# DDR32SS0_CTLPHY_WRAP_CTL_CFG_CTLCFG register map
Vendor: Texas Instruments
Registers are 32-bit, read-write, reset 0x0 unless marked. A register's access mark holds for its fields unless they carry their own. Offsets are as the file gives them; [hi:lo] are bit positions; {n}, {i} and the like mark numbered series.

## DDR32SS0_CTLPHY_WRAP_CTL_CFG_CTLCFG (part 6 of 11)
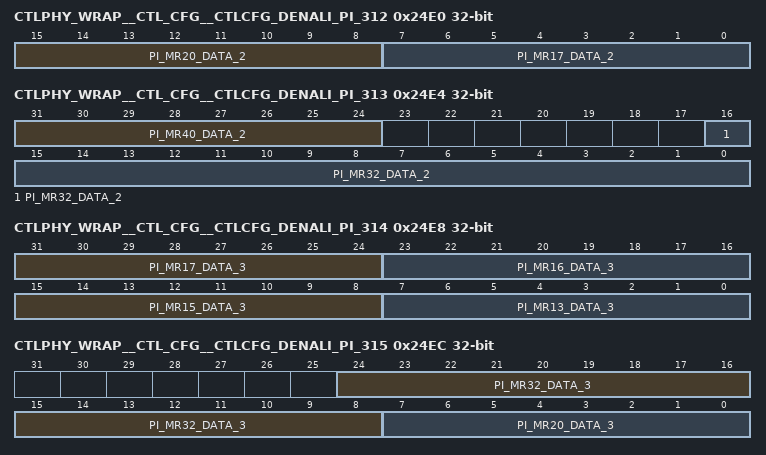
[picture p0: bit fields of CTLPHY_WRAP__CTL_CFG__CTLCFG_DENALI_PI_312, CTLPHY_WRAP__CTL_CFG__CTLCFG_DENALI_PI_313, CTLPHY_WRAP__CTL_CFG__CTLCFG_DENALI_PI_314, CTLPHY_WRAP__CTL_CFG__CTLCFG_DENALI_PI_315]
0x24E0 CTLPHY_WRAP__CTL_CFG__CTLCFG_DENALI_PI_312
  [15:8] PI_MR20_DATA_2 — Data to program into memory mode register 20 for chip select 2.
  [7:0] PI_MR17_DATA_2 — Data to program into memory mode register 17 for chip select 2.
0x24E4 CTLPHY_WRAP__CTL_CFG__CTLCFG_DENALI_PI_313
  [31:24] PI_MR40_DATA_2 — Data to program into memory mode register 40 for chip select 2.
  [16:0] PI_MR32_DATA_2 — Data to program into memory mode register 32 for chip select 2.
0x24E8 CTLPHY_WRAP__CTL_CFG__CTLCFG_DENALI_PI_314
  [31:24] PI_MR17_DATA_3 — Data to program into memory mode register 17 for chip select 3.
  [23:16] PI_MR16_DATA_3 — Data to program into memory mode register 16 for chip select 3.
  [15:8] PI_MR15_DATA_3 — Data to program into memory mode register 15 for chip select 3.
  [7:0] PI_MR13_DATA_3 — Data to program into memory mode register 13 for chip select 3.
0x24EC CTLPHY_WRAP__CTL_CFG__CTLCFG_DENALI_PI_315
  [24:8] PI_MR32_DATA_3 — Data to program into memory mode register 32 for chip select 3.
  [7:0] PI_MR20_DATA_3 — Data to program into memory mode register 20 for chip select 3.
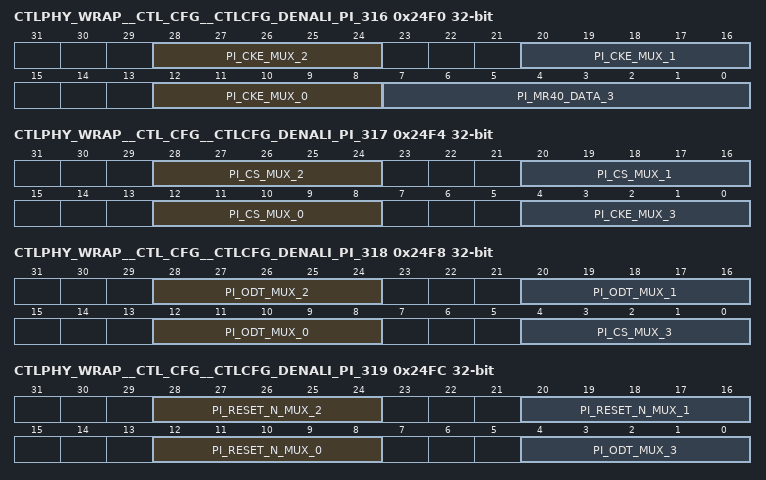
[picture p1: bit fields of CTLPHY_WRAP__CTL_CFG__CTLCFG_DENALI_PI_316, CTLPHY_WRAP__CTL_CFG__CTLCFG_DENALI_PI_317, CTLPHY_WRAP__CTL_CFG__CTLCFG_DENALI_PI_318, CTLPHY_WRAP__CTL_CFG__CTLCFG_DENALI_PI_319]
0x24F0 CTLPHY_WRAP__CTL_CFG__CTLCFG_DENALI_PI_316
  [28:24] PI_CKE_MUX_2 — Command pin CKE_2 mux selector
  [20:16] PI_CKE_MUX_1 — Command pin CKE_1 mux selector
  [12:8] PI_CKE_MUX_0 — Command pin CKE_0 mux selector
  [7:0] PI_MR40_DATA_3 — Data to program into memory mode register 40 for chip select 3.
0x24F4 CTLPHY_WRAP__CTL_CFG__CTLCFG_DENALI_PI_317
  [28:24] PI_CS_MUX_2 — Command pin CS_2 mux selector
  [20:16] PI_CS_MUX_1 — Command pin CS_1 mux selector
  [12:8] PI_CS_MUX_0 — Command pin CS_0 mux selector
  [4:0] PI_CKE_MUX_3 — Command pin CKE_3 mux selector
0x24F8 CTLPHY_WRAP__CTL_CFG__CTLCFG_DENALI_PI_318
  [28:24] PI_ODT_MUX_2 — Command pin ODT_2 mux selector
  [20:16] PI_ODT_MUX_1 — Command pin ODT_1 mux selector
  [12:8] PI_ODT_MUX_0 — Command pin ODT_0 mux selector
  [4:0] PI_CS_MUX_3 — Command pin CS_3 mux selector
0x24FC CTLPHY_WRAP__CTL_CFG__CTLCFG_DENALI_PI_319
  [28:24] PI_RESET_N_MUX_2 — Command pin RESET_N_2 mux selector
  [20:16] PI_RESET_N_MUX_1 — Command pin RESET_N_1 mux selector
  [12:8] PI_RESET_N_MUX_0 — Command pin RESET_N_0 mux selector
  [4:0] PI_ODT_MUX_3 — Command pin ODT_3 mux selector
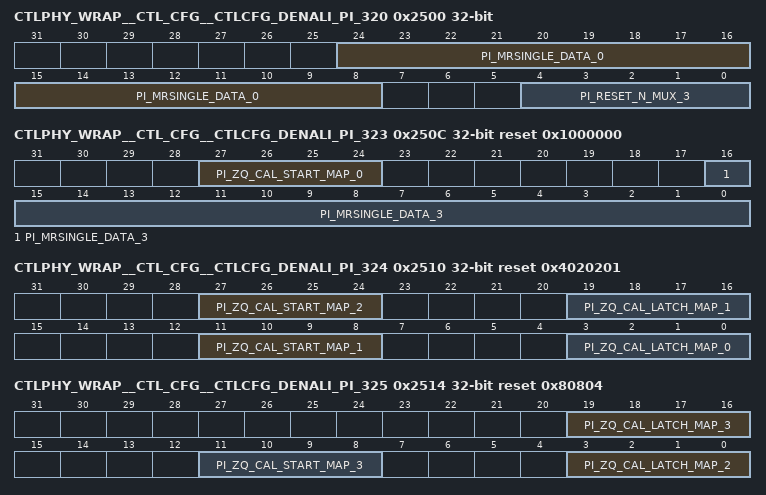
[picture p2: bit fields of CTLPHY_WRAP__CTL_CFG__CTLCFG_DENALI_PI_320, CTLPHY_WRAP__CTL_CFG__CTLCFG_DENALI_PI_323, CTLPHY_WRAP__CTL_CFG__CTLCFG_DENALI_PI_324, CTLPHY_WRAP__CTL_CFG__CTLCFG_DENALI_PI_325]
0x2500 CTLPHY_WRAP__CTL_CFG__CTLCFG_DENALI_PI_320
  [24:8] PI_MRSINGLE_DATA_0 — Data to program into memory mode register single write to chip select 0.
  [4:0] PI_RESET_N_MUX_3 — Command pin RESET_N_3 mux selector
0x2504 CTLPHY_WRAP__CTL_CFG__CTLCFG_DENALI_PI_321
  [16:0] PI_MRSINGLE_DATA_1 — Data to program into memory mode register single write to chip select 1.
0x2508 CTLPHY_WRAP__CTL_CFG__CTLCFG_DENALI_PI_322
  [16:0] PI_MRSINGLE_DATA_2 — Data to program into memory mode register single write to chip select 2.
0x250C CTLPHY_WRAP__CTL_CFG__CTLCFG_DENALI_PI_323 reset 0x1000000
  [27:24] PI_ZQ_CAL_START_MAP_0 — Defines which chip select[s] will receive ZQ calibration start commands simultaneously on iteration 0 of the ZQ START initialization and periodic command sequences. Clear to all zeros for no ZQ START commands.
  [16:0] PI_MRSINGLE_DATA_3 — Data to program into memory mode register single write to chip select 3.
0x2510 CTLPHY_WRAP__CTL_CFG__CTLCFG_DENALI_PI_324 reset 0x4020201
  [27:24] PI_ZQ_CAL_START_MAP_2 — Defines which chip select[s] will receive ZQ calibration start commands simultaneously on iteration 2 of the ZQ START initialization and periodic command sequences. Clear to all zeros for no ZQ START commands.
  [19:16] PI_ZQ_CAL_LATCH_MAP_1 — Defines which chip select[s] will receive ZQ calibration latch commands simultaneously on iteration 1 of the ZQ LATCH initialization and periodic command sequences. Clear to all zeros for no ZQ LATCH commands.
  [11:8] PI_ZQ_CAL_START_MAP_1 — Defines which chip select[s] will receive ZQ calibration start commands simultaneously on iteration 1 of the ZQ START initialization and periodic command sequences. Clear to all zeros for no ZQ START commands.
  [3:0] PI_ZQ_CAL_LATCH_MAP_0 — Defines which chip select[s] will receive ZQ calibration latch commands simultaneously on iteration 0 of the ZQ LATCH initialization and periodic command sequences. Clear to all zeros for no ZQ LATCH commands.
0x2514 CTLPHY_WRAP__CTL_CFG__CTLCFG_DENALI_PI_325 reset 0x80804
  [19:16] PI_ZQ_CAL_LATCH_MAP_3 — Defines which chip select[s] will receive ZQ calibration latch commands simultaneously on iteration 3 of the ZQ LATCH initialization and periodic command sequences. Clear to all zeros for no ZQ LATCH commands.
  [11:8] PI_ZQ_CAL_START_MAP_3 — Defines which chip select[s] will receive ZQ calibration start commands simultaneously on iteration 3 of the ZQ START initialization and periodic command sequences. Clear to all zeros for no ZQ START commands.
  [3:0] PI_ZQ_CAL_LATCH_MAP_2 — Defines which chip select[s] will receive ZQ calibration latch commands simultaneously on iteration 2 of the ZQ LATCH initialization and periodic command sequences. Clear to all zeros for no ZQ LATCH commands.
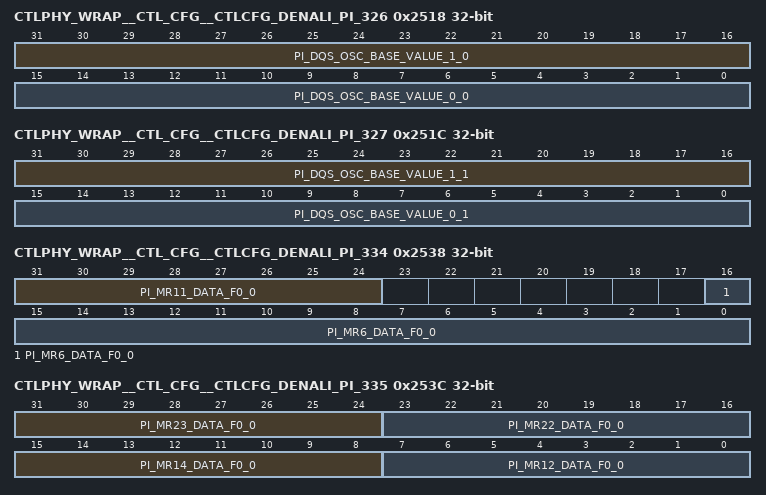
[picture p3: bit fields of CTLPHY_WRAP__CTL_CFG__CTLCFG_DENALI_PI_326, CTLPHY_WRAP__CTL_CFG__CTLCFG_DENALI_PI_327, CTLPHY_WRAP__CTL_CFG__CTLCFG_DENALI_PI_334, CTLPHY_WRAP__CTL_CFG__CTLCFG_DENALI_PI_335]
0x2518 CTLPHY_WRAP__CTL_CFG__CTLCFG_DENALI_PI_326
  [31:16] PI_DQS_OSC_BASE_VALUE_1_0 — Base value for comparison of oscillator measurement for device 1 of rank 0
  [15:0] PI_DQS_OSC_BASE_VALUE_0_0 — Base value for comparison of oscillator measurement for device 0 of rank 0
0x251C CTLPHY_WRAP__CTL_CFG__CTLCFG_DENALI_PI_327
  [31:16] PI_DQS_OSC_BASE_VALUE_1_1 — Base value for comparison of oscillator measurement for device 1 of rank 1
  [15:0] PI_DQS_OSC_BASE_VALUE_0_1 — Base value for comparison of oscillator measurement for device 0 of rank 1
{0x2000+4i} CTLPHY_WRAP__CTL_CFG__CTLCFG_DENALI_PI_{i} (i=328..333)
  [16:0] PI_MR{i-328}_DATA_F0_0 — Data to program into memory mode register {i-328} for chip select 0 for frequency set 0.
0x2538 CTLPHY_WRAP__CTL_CFG__CTLCFG_DENALI_PI_334
  [31:24] PI_MR11_DATA_F0_0 — Data to program into memory mode register 11 for chip select 0 for frequency set 0.
  [16:0] PI_MR6_DATA_F0_0 — Data to program into memory mode register 6 for chip select 0 for frequency set 0.
0x253C CTLPHY_WRAP__CTL_CFG__CTLCFG_DENALI_PI_335
  [31:24] PI_MR23_DATA_F0_0 — Data to program into memory mode register 23 for chip select 0 for frequency set 0.
  [23:16] PI_MR22_DATA_F0_0 — Data to program into memory mode register 22 for chip select 0 for frequency set 0.
  [15:8] PI_MR14_DATA_F0_0 — Data to program into memory mode register 14 for chip select 0 for frequency set 0.
  [7:0] PI_MR12_DATA_F0_0 — Data to program into memory mode register 12 for chip select 0 for frequency set 0.
{0x2000+4i} CTLPHY_WRAP__CTL_CFG__CTLCFG_DENALI_PI_{i} (i=336..341)
  [16:0] PI_MR{i-336}_DATA_F1_0 — Data to program into memory mode register {i-336} for chip select 0 for frequency set 1.
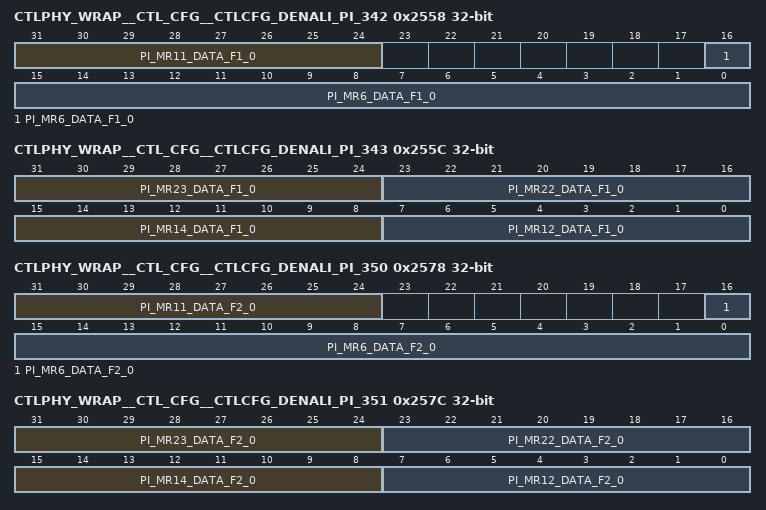
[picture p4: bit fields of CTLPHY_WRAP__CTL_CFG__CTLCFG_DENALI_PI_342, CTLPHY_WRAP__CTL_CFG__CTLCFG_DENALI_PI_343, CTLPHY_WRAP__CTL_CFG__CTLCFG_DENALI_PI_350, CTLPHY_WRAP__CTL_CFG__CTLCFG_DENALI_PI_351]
0x2558 CTLPHY_WRAP__CTL_CFG__CTLCFG_DENALI_PI_342
  [31:24] PI_MR11_DATA_F1_0 — Data to program into memory mode register 11 for chip select 0 for frequency set 1.
  [16:0] PI_MR6_DATA_F1_0 — Data to program into memory mode register 6 for chip select 0 for frequency set 1.
0x255C CTLPHY_WRAP__CTL_CFG__CTLCFG_DENALI_PI_343
  [31:24] PI_MR23_DATA_F1_0 — Data to program into memory mode register 23 for chip select 0 for frequency set 1.
  [23:16] PI_MR22_DATA_F1_0 — Data to program into memory mode register 22 for chip select 0 for frequency set 1.
  [15:8] PI_MR14_DATA_F1_0 — Data to program into memory mode register 14 for chip select 0 for frequency set 1.
  [7:0] PI_MR12_DATA_F1_0 — Data to program into memory mode register 12 for chip select 0 for frequency set 1.
{0x2000+4i} CTLPHY_WRAP__CTL_CFG__CTLCFG_DENALI_PI_{i} (i=344..349)
  [16:0] PI_MR{i-344}_DATA_F2_0 — Data to program into memory mode register {i-344} for chip select 0 for frequency set 2.
0x2578 CTLPHY_WRAP__CTL_CFG__CTLCFG_DENALI_PI_350
  [31:24] PI_MR11_DATA_F2_0 — Data to program into memory mode register 11 for chip select 0 for frequency set 2.
  [16:0] PI_MR6_DATA_F2_0 — Data to program into memory mode register 6 for chip select 0 for frequency set 2.
0x257C CTLPHY_WRAP__CTL_CFG__CTLCFG_DENALI_PI_351
  [31:24] PI_MR23_DATA_F2_0 — Data to program into memory mode register 23 for chip select 0 for frequency set 2.
  [23:16] PI_MR22_DATA_F2_0 — Data to program into memory mode register 22 for chip select 0 for frequency set 2.
  [15:8] PI_MR14_DATA_F2_0 — Data to program into memory mode register 14 for chip select 0 for frequency set 2.
  [7:0] PI_MR12_DATA_F2_0 — Data to program into memory mode register 12 for chip select 0 for frequency set 2.
{0x2000+4i} CTLPHY_WRAP__CTL_CFG__CTLCFG_DENALI_PI_{i} (i=352..357)
  [16:0] PI_MR{i-352}_DATA_F0_1 — Data to program into memory mode register {i-352} for chip select 1 for frequency set 0.
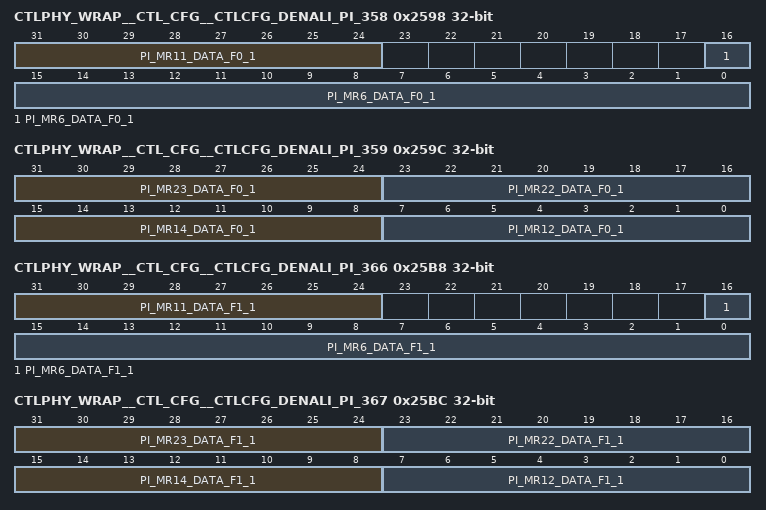
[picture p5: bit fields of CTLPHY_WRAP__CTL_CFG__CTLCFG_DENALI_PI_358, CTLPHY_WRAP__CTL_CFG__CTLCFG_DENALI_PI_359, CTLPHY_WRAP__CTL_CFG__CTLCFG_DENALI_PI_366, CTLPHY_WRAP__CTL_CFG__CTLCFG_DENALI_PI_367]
0x2598 CTLPHY_WRAP__CTL_CFG__CTLCFG_DENALI_PI_358
  [31:24] PI_MR11_DATA_F0_1 — Data to program into memory mode register 11 for chip select 1 for frequency set 0.
  [16:0] PI_MR6_DATA_F0_1 — Data to program into memory mode register 6 for chip select 1 for frequency set 0.
0x259C CTLPHY_WRAP__CTL_CFG__CTLCFG_DENALI_PI_359
  [31:24] PI_MR23_DATA_F0_1 — Data to program into memory mode register 23 for chip select 1 for frequency set 0.
  [23:16] PI_MR22_DATA_F0_1 — Data to program into memory mode register 22 for chip select 1 for frequency set 0.
  [15:8] PI_MR14_DATA_F0_1 — Data to program into memory mode register 14 for chip select 1 for frequency set 0.
  [7:0] PI_MR12_DATA_F0_1 — Data to program into memory mode register 12 for chip select 1 for frequency set 0.
{0x2000+4i} CTLPHY_WRAP__CTL_CFG__CTLCFG_DENALI_PI_{i} (i=360..365)
  [16:0] PI_MR{i-360}_DATA_F1_1 — Data to program into memory mode register {i-360} for chip select 1 for frequency set 1.
0x25B8 CTLPHY_WRAP__CTL_CFG__CTLCFG_DENALI_PI_366
  [31:24] PI_MR11_DATA_F1_1 — Data to program into memory mode register 11 for chip select 1 for frequency set 1.
  [16:0] PI_MR6_DATA_F1_1 — Data to program into memory mode register 6 for chip select 1 for frequency set 1.
0x25BC CTLPHY_WRAP__CTL_CFG__CTLCFG_DENALI_PI_367
  [31:24] PI_MR23_DATA_F1_1 — Data to program into memory mode register 23 for chip select 1 for frequency set 1.
  [23:16] PI_MR22_DATA_F1_1 — Data to program into memory mode register 22 for chip select 1 for frequency set 1.
  [15:8] PI_MR14_DATA_F1_1 — Data to program into memory mode register 14 for chip select 1 for frequency set 1.
  [7:0] PI_MR12_DATA_F1_1 — Data to program into memory mode register 12 for chip select 1 for frequency set 1.
{0x2000+4i} CTLPHY_WRAP__CTL_CFG__CTLCFG_DENALI_PI_{i} (i=368..373)
  [16:0] PI_MR{i-368}_DATA_F2_1 — Data to program into memory mode register {i-368} for chip select 1 for frequency set 2.
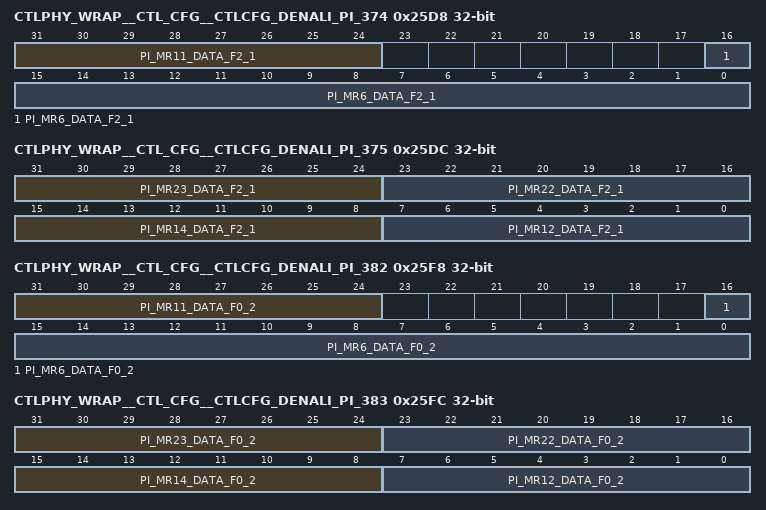
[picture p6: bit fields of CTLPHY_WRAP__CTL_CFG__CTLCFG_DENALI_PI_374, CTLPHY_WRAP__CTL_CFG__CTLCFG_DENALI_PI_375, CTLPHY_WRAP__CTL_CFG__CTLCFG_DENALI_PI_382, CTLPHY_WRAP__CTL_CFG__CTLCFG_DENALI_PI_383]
0x25D8 CTLPHY_WRAP__CTL_CFG__CTLCFG_DENALI_PI_374
  [31:24] PI_MR11_DATA_F2_1 — Data to program into memory mode register 11 for chip select 1 for frequency set 2.
  [16:0] PI_MR6_DATA_F2_1 — Data to program into memory mode register 6 for chip select 1 for frequency set 2.
0x25DC CTLPHY_WRAP__CTL_CFG__CTLCFG_DENALI_PI_375
  [31:24] PI_MR23_DATA_F2_1 — Data to program into memory mode register 23 for chip select 1 for frequency set 2.
  [23:16] PI_MR22_DATA_F2_1 — Data to program into memory mode register 22 for chip select 1 for frequency set 2.
  [15:8] PI_MR14_DATA_F2_1 — Data to program into memory mode register 14 for chip select 1 for frequency set 2.
  [7:0] PI_MR12_DATA_F2_1 — Data to program into memory mode register 12 for chip select 1 for frequency set 2.
{0x2000+4i} CTLPHY_WRAP__CTL_CFG__CTLCFG_DENALI_PI_{i} (i=376..381)
  [16:0] PI_MR{i-376}_DATA_F0_2 — Data to program into memory mode register {i-376} for chip select 2 for frequency set 0.
0x25F8 CTLPHY_WRAP__CTL_CFG__CTLCFG_DENALI_PI_382
  [31:24] PI_MR11_DATA_F0_2 — Data to program into memory mode register 11 for chip select 2 for frequency set 0.
  [16:0] PI_MR6_DATA_F0_2 — Data to program into memory mode register 6 for chip select 2 for frequency set 0.
0x25FC CTLPHY_WRAP__CTL_CFG__CTLCFG_DENALI_PI_383
  [31:24] PI_MR23_DATA_F0_2 — Data to program into memory mode register 23 for chip select 2 for frequency set 0.
  [23:16] PI_MR22_DATA_F0_2 — Data to program into memory mode register 22 for chip select 2 for frequency set 0.
  [15:8] PI_MR14_DATA_F0_2 — Data to program into memory mode register 14 for chip select 2 for frequency set 0.
  [7:0] PI_MR12_DATA_F0_2 — Data to program into memory mode register 12 for chip select 2 for frequency set 0.
{0x2000+4i} CTLPHY_WRAP__CTL_CFG__CTLCFG_DENALI_PI_{i} (i=384..389)
  [16:0] PI_MR{i-384}_DATA_F1_2 — Data to program into memory mode register {i-384} for chip select 2 for frequency set 1.
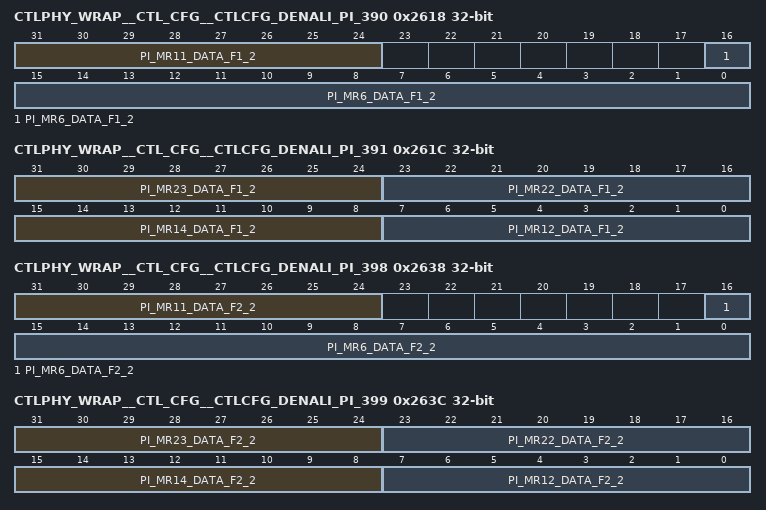
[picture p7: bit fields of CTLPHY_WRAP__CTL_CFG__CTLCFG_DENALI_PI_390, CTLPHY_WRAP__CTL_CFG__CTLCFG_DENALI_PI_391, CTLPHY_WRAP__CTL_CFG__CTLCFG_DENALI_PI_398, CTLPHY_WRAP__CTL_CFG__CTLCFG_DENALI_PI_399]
0x2618 CTLPHY_WRAP__CTL_CFG__CTLCFG_DENALI_PI_390
  [31:24] PI_MR11_DATA_F1_2 — Data to program into memory mode register 11 for chip select 2 for frequency set 1.
  [16:0] PI_MR6_DATA_F1_2 — Data to program into memory mode register 6 for chip select 2 for frequency set 1.
0x261C CTLPHY_WRAP__CTL_CFG__CTLCFG_DENALI_PI_391
  [31:24] PI_MR23_DATA_F1_2 — Data to program into memory mode register 23 for chip select 2 for frequency set 1.
  [23:16] PI_MR22_DATA_F1_2 — Data to program into memory mode register 22 for chip select 2 for frequency set 1.
  [15:8] PI_MR14_DATA_F1_2 — Data to program into memory mode register 14 for chip select 2 for frequency set 1.
  [7:0] PI_MR12_DATA_F1_2 — Data to program into memory mode register 12 for chip select 2 for frequency set 1.
{0x2000+4i} CTLPHY_WRAP__CTL_CFG__CTLCFG_DENALI_PI_{i} (i=392..397)
  [16:0] PI_MR{i-392}_DATA_F2_2 — Data to program into memory mode register {i-392} for chip select 2 for frequency set 2.
0x2638 CTLPHY_WRAP__CTL_CFG__CTLCFG_DENALI_PI_398
  [31:24] PI_MR11_DATA_F2_2 — Data to program into memory mode register 11 for chip select 2 for frequency set 2.
  [16:0] PI_MR6_DATA_F2_2 — Data to program into memory mode register 6 for chip select 2 for frequency set 2.
0x263C CTLPHY_WRAP__CTL_CFG__CTLCFG_DENALI_PI_399
  [31:24] PI_MR23_DATA_F2_2 — Data to program into memory mode register 23 for chip select 2 for frequency set 2.
  [23:16] PI_MR22_DATA_F2_2 — Data to program into memory mode register 22 for chip select 2 for frequency set 2.
  [15:8] PI_MR14_DATA_F2_2 — Data to program into memory mode register 14 for chip select 2 for frequency set 2.
  [7:0] PI_MR12_DATA_F2_2 — Data to program into memory mode register 12 for chip select 2 for frequency set 2.
{0x2000+4i} CTLPHY_WRAP__CTL_CFG__CTLCFG_DENALI_PI_{i} (i=400..405)
  [16:0] PI_MR{i-400}_DATA_F0_3 — Data to program into memory mode register {i-400} for chip select 3 for frequency set 0.
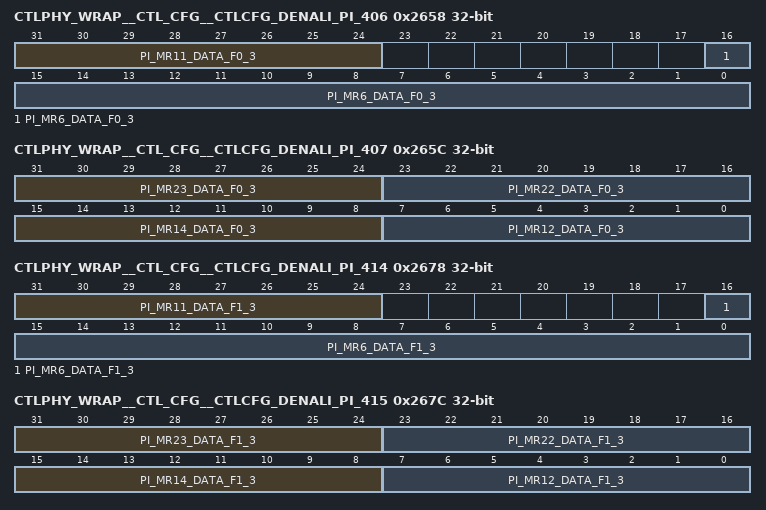
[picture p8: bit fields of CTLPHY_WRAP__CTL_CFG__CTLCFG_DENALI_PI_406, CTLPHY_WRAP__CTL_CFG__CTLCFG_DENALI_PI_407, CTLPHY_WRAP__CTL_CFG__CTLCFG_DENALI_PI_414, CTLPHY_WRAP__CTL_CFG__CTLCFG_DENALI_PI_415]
0x2658 CTLPHY_WRAP__CTL_CFG__CTLCFG_DENALI_PI_406
  [31:24] PI_MR11_DATA_F0_3 — Data to program into memory mode register 11 for chip select 3 for frequency set 0.
  [16:0] PI_MR6_DATA_F0_3 — Data to program into memory mode register 6 for chip select 3 for frequency set 0.
0x265C CTLPHY_WRAP__CTL_CFG__CTLCFG_DENALI_PI_407
  [31:24] PI_MR23_DATA_F0_3 — Data to program into memory mode register 23 for chip select 3 for frequency set 0.
  [23:16] PI_MR22_DATA_F0_3 — Data to program into memory mode register 22 for chip select 3 for frequency set 0.
  [15:8] PI_MR14_DATA_F0_3 — Data to program into memory mode register 14 for chip select 3 for frequency set 0.
  [7:0] PI_MR12_DATA_F0_3 — Data to program into memory mode register 12 for chip select 3 for frequency set 0.
{0x2000+4i} CTLPHY_WRAP__CTL_CFG__CTLCFG_DENALI_PI_{i} (i=408..413)
  [16:0] PI_MR{i-408}_DATA_F1_3 — Data to program into memory mode register {i-408} for chip select 3 for frequency set 1.
0x2678 CTLPHY_WRAP__CTL_CFG__CTLCFG_DENALI_PI_414
  [31:24] PI_MR11_DATA_F1_3 — Data to program into memory mode register 11 for chip select 3 for frequency set 1.
  [16:0] PI_MR6_DATA_F1_3 — Data to program into memory mode register 6 for chip select 3 for frequency set 1.
0x267C CTLPHY_WRAP__CTL_CFG__CTLCFG_DENALI_PI_415
  [31:24] PI_MR23_DATA_F1_3 — Data to program into memory mode register 23 for chip select 3 for frequency set 1.
  [23:16] PI_MR22_DATA_F1_3 — Data to program into memory mode register 22 for chip select 3 for frequency set 1.
  [15:8] PI_MR14_DATA_F1_3 — Data to program into memory mode register 14 for chip select 3 for frequency set 1.
  [7:0] PI_MR12_DATA_F1_3 — Data to program into memory mode register 12 for chip select 3 for frequency set 1.
{0x2000+4i} CTLPHY_WRAP__CTL_CFG__CTLCFG_DENALI_PI_{i} (i=416..421)
  [16:0] PI_MR{i-416}_DATA_F2_3 — Data to program into memory mode register {i-416} for chip select 3 for frequency set 2.
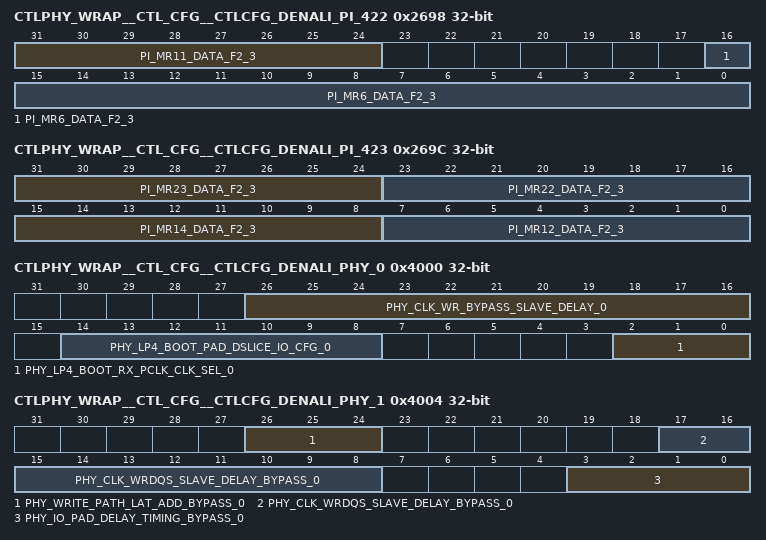
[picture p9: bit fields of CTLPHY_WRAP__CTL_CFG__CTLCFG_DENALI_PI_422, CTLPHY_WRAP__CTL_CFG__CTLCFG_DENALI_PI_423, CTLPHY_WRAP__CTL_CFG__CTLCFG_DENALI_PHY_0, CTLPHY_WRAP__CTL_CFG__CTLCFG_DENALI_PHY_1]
0x2698 CTLPHY_WRAP__CTL_CFG__CTLCFG_DENALI_PI_422
  [31:24] PI_MR11_DATA_F2_3 — Data to program into memory mode register 11 for chip select 3 for frequency set 2.
  [16:0] PI_MR6_DATA_F2_3 — Data to program into memory mode register 6 for chip select 3 for frequency set 2.
0x269C CTLPHY_WRAP__CTL_CFG__CTLCFG_DENALI_PI_423
  [31:24] PI_MR23_DATA_F2_3 — Data to program into memory mode register 23 for chip select 3 for frequency set 2.
  [23:16] PI_MR22_DATA_F2_3 — Data to program into memory mode register 22 for chip select 3 for frequency set 2.
  [15:8] PI_MR14_DATA_F2_3 — Data to program into memory mode register 14 for chip select 3 for frequency set 2.
  [7:0] PI_MR12_DATA_F2_3 — Data to program into memory mode register 12 for chip select 3 for frequency set 2.
0x4000 CTLPHY_WRAP__CTL_CFG__CTLCFG_DENALI_PHY_0
  [26:16] PHY_CLK_WR_BYPASS_SLAVE_DELAY_0 — Write data clock bypass mode target delay setting for slice 0.
  [14:8] PHY_LP4_BOOT_PAD_DSLICE_IO_CFG_0 — Controls PCLK/PARK pin for pad for slice 0 with boot frequency.
  [2:0] PHY_LP4_BOOT_RX_PCLK_CLK_SEL_0 — RX_PCLK boot clock frequency selection for slice 0.
0x4004 CTLPHY_WRAP__CTL_CFG__CTLCFG_DENALI_PHY_1
  [26:24] PHY_WRITE_PATH_LAT_ADD_BYPASS_0 — Number of cycles on bypass mode to delay the incoming dfi_wrdata_en/dfi_wrdata signals for slice 0.
  [17:8] PHY_CLK_WRDQS_SLAVE_DELAY_BYPASS_0 — Write DQS bypass mode target delay setting for slice 0.
  [3:0] PHY_IO_PAD_DELAY_TIMING_BYPASS_0 — Feedback pad's OPAD and IPAD delay timing on bypass mode for slice 0.
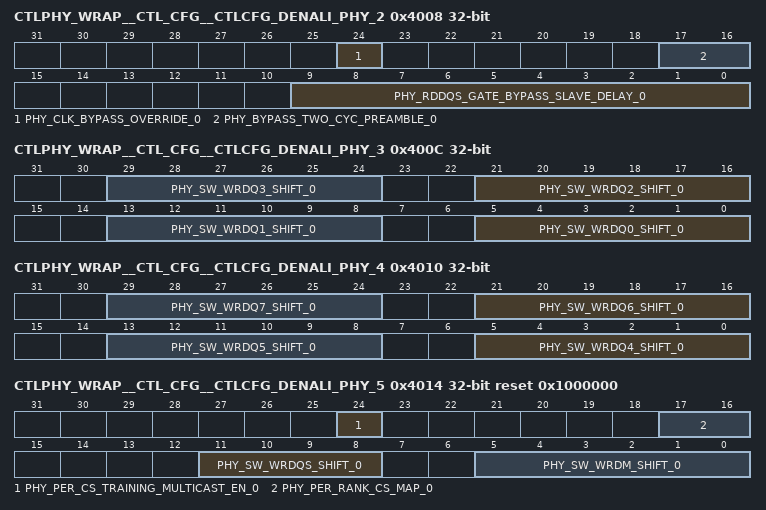
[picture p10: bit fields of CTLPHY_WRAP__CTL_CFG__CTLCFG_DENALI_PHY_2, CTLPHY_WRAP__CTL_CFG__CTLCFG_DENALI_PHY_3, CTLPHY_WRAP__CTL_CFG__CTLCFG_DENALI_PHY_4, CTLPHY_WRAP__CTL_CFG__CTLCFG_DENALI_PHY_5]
0x4008 CTLPHY_WRAP__CTL_CFG__CTLCFG_DENALI_PHY_2
  [24] PHY_CLK_BYPASS_OVERRIDE_0 — Bypass mode override setting for slice 0.
  [17:16] PHY_BYPASS_TWO_CYC_PREAMBLE_0 — Two_cycle_preamble for bypass mode for slice 0.
  [9:0] PHY_RDDQS_GATE_BYPASS_SLAVE_DELAY_0 — Read DQS bypass mode target delay setting for slice 0.
0x400C CTLPHY_WRAP__CTL_CFG__CTLCFG_DENALI_PHY_3
  [8n+5:8n] PHY_SW_WRDQ{n}_SHIFT_0 (n=0..3) — Manual override of automatic half_cycle_shift/cycle_shift for write DQ{n} for slice 0. Bit [0] enables override of half_cycle_shift. Bit [1] is the half_cycle_shift value. Bit [2] enables override of cycle shift. Bits [4:3] are the cycle_shift value.
0x4010 CTLPHY_WRAP__CTL_CFG__CTLCFG_DENALI_PHY_4
  [8n-27:8n-32] PHY_SW_WRDQ{n}_SHIFT_0 (n=4..7) — Manual override of automatic half_cycle_shift/cycle_shift for write DQ{n} for slice 0. Bit [0] enables override of half_cycle_shift. Bit [1] is the half_cycle_shift value. Bit [2] enables override of cycle shift. Bits [4:3] are the cycle_shift value.
0x4014 CTLPHY_WRAP__CTL_CFG__CTLCFG_DENALI_PHY_5 reset 0x1000000
  [24] PHY_PER_CS_TRAINING_MULTICAST_EN_0 — When set, a register write will update parameters for all ranks at the same time in slice 0. Set to 1 to enable.
  [17:16] PHY_PER_RANK_CS_MAP_0 — Per-rank CS map for slice 0. Setting a bit uses that CS for the rank, bit [0] uses CS0, bit [1] uses CS1, etc.
  [11:8] PHY_SW_WRDQS_SHIFT_0 — Manual override of automatic half_cycle_shift/cycle_shift for write DQS for slice 0. Bit [0] enables override of half_cycle_shift. Bit [1] is the half_cycle_shift value. Bit [2] enables override of cycle shift. Bit [3] is the cycle_shift value.
  [5:0] PHY_SW_WRDM_SHIFT_0 — Manual override of automatic half_cycle_shift/cycle_shift for write DM for slice 0. Bit [0] enables override of half_cycle_shift. Bit [1] is the half_cycle_shift value. Bit [2] enables override of cycle shift. Bits [4:3] are the cycle_shift value.
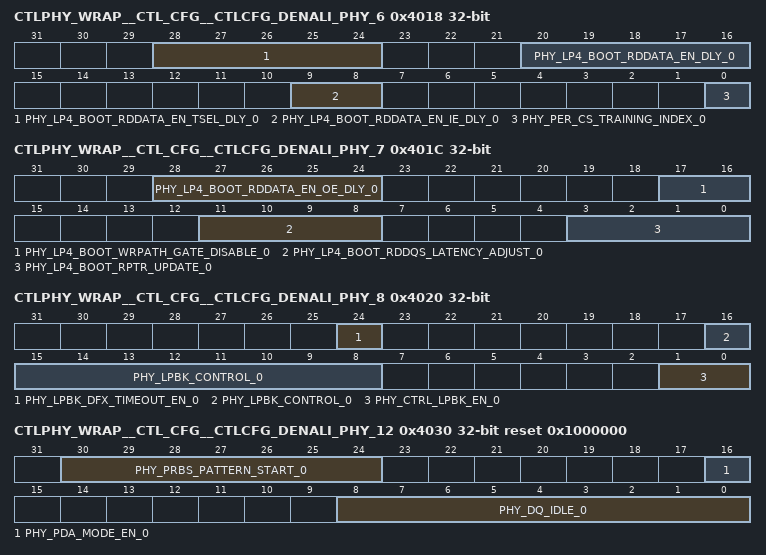
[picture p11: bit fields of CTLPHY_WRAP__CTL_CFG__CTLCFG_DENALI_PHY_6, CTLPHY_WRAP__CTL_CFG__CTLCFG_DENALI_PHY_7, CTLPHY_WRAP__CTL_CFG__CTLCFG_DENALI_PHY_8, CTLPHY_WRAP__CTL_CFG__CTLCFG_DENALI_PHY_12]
0x4018 CTLPHY_WRAP__CTL_CFG__CTLCFG_DENALI_PHY_6
  [28:24] PHY_LP4_BOOT_RDDATA_EN_TSEL_DLY_0 — For LPDDR4 boot frequency, the number of cycles that the dfi_rddata_en signal is earlier than necessary for TSEL enable generation for slice 0.
  [20:16] PHY_LP4_BOOT_RDDATA_EN_DLY_0 — For LPDDR4 boot frequency, the number of cycles that the dfi_rddata_en signal is early for slice 0.
  [9:8] PHY_LP4_BOOT_RDDATA_EN_IE_DLY_0 — For LPDDR4 boot frequency, the number of cycles that the dfi_rddata_en signal is earlier than necessary for input enable generation for slice 0.
  [0] PHY_PER_CS_TRAINING_INDEX_0 — For per-rank training, indicates which rank's paramters are read/written for slice 0.
0x401C CTLPHY_WRAP__CTL_CFG__CTLCFG_DENALI_PHY_7
  [28:24] PHY_LP4_BOOT_RDDATA_EN_OE_DLY_0 — For LPDDR4 boot frequency, the number of cycles that the dfi_rddata_en signal is earlier than necessary for extended OE generation for slice 0.
  [17:16] PHY_LP4_BOOT_WRPATH_GATE_DISABLE_0 — For LPDDR4 boot frequency, write path clock gating disable for slice 0. Bit [0]: disable pull in wrdata_en; Bit [1]: disable write path clock gating, clock always on
  [11:8] PHY_LP4_BOOT_RDDQS_LATENCY_ADJUST_0 — For LPDDR4 boot frequency, the number of cycles to delay the incoming dfi_rddata_en for read DQS gate generation for slice 0.
  [3:0] PHY_LP4_BOOT_RPTR_UPDATE_0 — For LPDDR4 boot frequency, the offset in cycles from the dfi_rddata_en signal to releasing data from the entry FIFO for slice 0.
0x4020 CTLPHY_WRAP__CTL_CFG__CTLCFG_DENALI_PHY_8
  [24] PHY_LPBK_DFX_TIMEOUT_EN_0 — Loopback read only test timeout mechanism enable for slice 0.
  [16:8] PHY_LPBK_CONTROL_0 — Loopback control bits for slice 0.
  [1:0] PHY_CTRL_LPBK_EN_0 — Loopback control en for slice 0.
0x4024 CTLPHY_WRAP__CTL_CFG__CTLCFG_DENALI_PHY_9
  [0] PHY_GATE_DELAY_COMP_DISABLE_0 — use the control whether to compensate half_cycle when gate_target_delay is larger than half_cycle for the gate close for slice 0.
0x4028 CTLPHY_WRAP__CTL_CFG__CTLCFG_DENALI_PHY_10
  [31:0] PHY_AUTO_TIMING_MARGIN_CONTROL_0 — Auto timing marging control bits for slice 0.
0x402C CTLPHY_WRAP__CTL_CFG__CTLCFG_DENALI_PHY_11 ro
  [27:0] PHY_AUTO_TIMING_MARGIN_OBS_0 — Observation register for the auto_timing_margin for slice 0. READ-ONLY
0x4030 CTLPHY_WRAP__CTL_CFG__CTLCFG_DENALI_PHY_12 reset 0x1000000
  [30:24] PHY_PRBS_PATTERN_START_0 — PRBS7 start pattern for slice 0.
  [16] PHY_PDA_MODE_EN_0 — When set to 1, the invalid DQs will be driven by the dfi_wrdata to make sure the tpda_s and tpda_h's timing is meet for slice 0.
  [8:0] PHY_DQ_IDLE_0 — When set to 1, the inavlid DQ will be driven to high, when set to 0, the invalid DQ will be driven to low for slice 0.
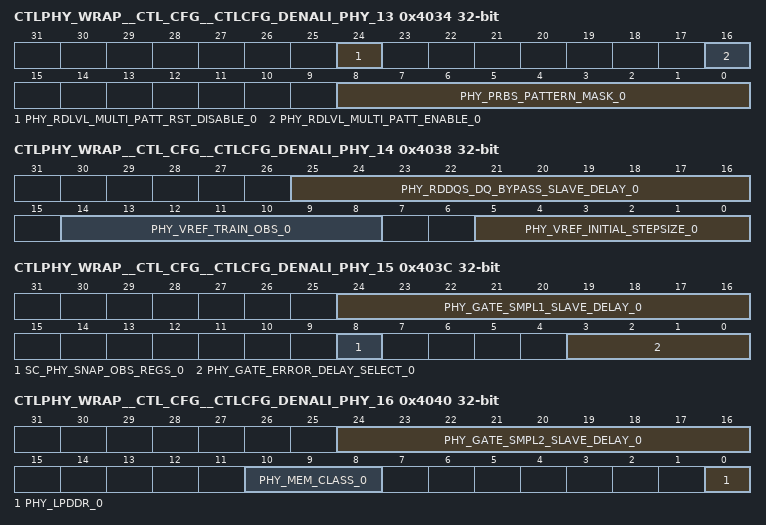
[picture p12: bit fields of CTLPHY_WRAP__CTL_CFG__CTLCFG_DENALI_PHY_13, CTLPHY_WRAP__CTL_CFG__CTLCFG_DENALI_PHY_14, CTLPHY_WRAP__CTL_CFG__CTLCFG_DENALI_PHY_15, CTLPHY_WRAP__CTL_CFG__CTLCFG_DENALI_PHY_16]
0x4034 CTLPHY_WRAP__CTL_CFG__CTLCFG_DENALI_PHY_13
  [24] PHY_RDLVL_MULTI_PATT_RST_DISABLE_0 — Read Leveling read level windows disable reset for slice 0.
  [16] PHY_RDLVL_MULTI_PATT_ENABLE_0 — Read Leveling Multi-pattern enable for slice 0.
  [8:0] PHY_PRBS_PATTERN_MASK_0 — PRBS7 mask signal for slice 0.
0x4038 CTLPHY_WRAP__CTL_CFG__CTLCFG_DENALI_PHY_14 access per field
  [25:16] PHY_RDDQS_DQ_BYPASS_SLAVE_DELAY_0 rw — Read DQS data clock bypass mode target delay setting for slice 0.
  [14:8] PHY_VREF_TRAIN_OBS_0 ro — Observation register for best vref value for slice 0. READ-ONLY
  [5:0] PHY_VREF_INITIAL_STEPSIZE_0 rw — Data slice initial VREF training step size for slice 0.
0x403C CTLPHY_WRAP__CTL_CFG__CTLCFG_DENALI_PHY_15 access per field
  [24:16] PHY_GATE_SMPL1_SLAVE_DELAY_0 rw — Number of cycles to delay the read DQS gate signal to generate gate1 signal for on-the-fly read DQS training for slice 0.
  [8] SC_PHY_SNAP_OBS_REGS_0 wo — Initiates a snapshot of the internal observation registers for slice 0. Set to 1 to trigger. WRITE-ONLY
  [3:0] PHY_GATE_ERROR_DELAY_SELECT_0 rw — Number of cycles to wait for the DQS gate to close before flagging an error for slice 0.
0x4040 CTLPHY_WRAP__CTL_CFG__CTLCFG_DENALI_PHY_16
  [24:16] PHY_GATE_SMPL2_SLAVE_DELAY_0 — Number of cycles to delay the read DQS gate signal to generate gate2 signal for on-the-fly read DQS training for slice 0.
  [10:8] PHY_MEM_CLASS_0 — Indicates the type of DRAM for slice 0. 0 for DDR3, 1 for DDR4, 2 for DDR5, 4 for LPDDR2, 5 for LPDDR3. 6 for LPDDR4
  [0] PHY_LPDDR_0 — Adds a cycle of delay for the slice 0 to match the address slice. Set to 1 to add a cycle
0x4044 CTLPHY_WRAP__CTL_CFG__CTLCFG_DENALI_PHY_17
  [1:0] ON_FLY_GATE_ADJUST_EN_0 — Control the on-the-fly gate adjustment for slice 0.
0x4048 CTLPHY_WRAP__CTL_CFG__CTLCFG_DENALI_PHY_18 ro
  [31:0] PHY_GATE_TRACKING_OBS_0 — Report the on-the-fly gate measurement result for slice 0. READ-ONLY
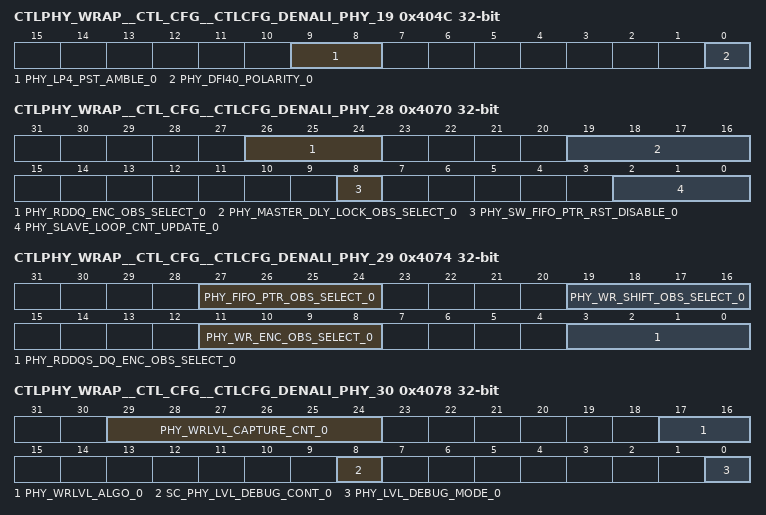
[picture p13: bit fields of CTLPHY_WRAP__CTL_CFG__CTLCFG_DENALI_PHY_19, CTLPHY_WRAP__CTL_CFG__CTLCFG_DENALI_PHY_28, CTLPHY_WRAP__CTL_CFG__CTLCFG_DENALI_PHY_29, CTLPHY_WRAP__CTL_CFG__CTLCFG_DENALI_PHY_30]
0x404C CTLPHY_WRAP__CTL_CFG__CTLCFG_DENALI_PHY_19
  [9:8] PHY_LP4_PST_AMBLE_0 — Controls the read postamble extension for LPDDR4 for slice 0.
  [0] PHY_DFI40_POLARITY_0 — Indicates the dfi_wrdata_cs_n and dfi_rddata_cs_n is low active or high active for slice 0.
{0x4000+4i} CTLPHY_WRAP__CTL_CFG__CTLCFG_DENALI_PHY_{i} (i=20..27)
  [31:0] PHY_RDLVL_PATT{i-12}_0 — Read leveling pattern {i-12} data for slice 0.
0x4070 CTLPHY_WRAP__CTL_CFG__CTLCFG_DENALI_PHY_28
  [26:24] PHY_RDDQ_ENC_OBS_SELECT_0 — Select value to map the internal read DQ target delay encoded settings to the accessible read DQ encoded target delay observation register for slice 0.
  [19:16] PHY_MASTER_DLY_LOCK_OBS_SELECT_0 — Select value to map the internal controller delay observation registers to the accessible controller delay observation register for slice 0.
  [8] PHY_SW_FIFO_PTR_RST_DISABLE_0 — Disables automatic reset of the read entry FIFO pointers for slice 0. Set to 1 to disable automatic resets.
  [2:0] PHY_SLAVE_LOOP_CNT_UPDATE_0 — Reserved for future use for slice 0.
0x4074 CTLPHY_WRAP__CTL_CFG__CTLCFG_DENALI_PHY_29
  [27:24] PHY_FIFO_PTR_OBS_SELECT_0 — Select value to map the internal read entry FIFO read/write pointers to the accessible read entry FIFO pointer observation register for slice 0.
  [19:16] PHY_WR_SHIFT_OBS_SELECT_0 — Select value to map the internal write DQ/DQS automatic cycle/half_cycle shift settings to the accessible write DQ/DQS shift observation register for slice 0.
  [11:8] PHY_WR_ENC_OBS_SELECT_0 — Select value to map the internal write DQ target delay encoded settings to the accessible write DQ encoded target delay observation register for slice 0.
  [3:0] PHY_RDDQS_DQ_ENC_OBS_SELECT_0 — Select value to map the internal read DQS DQ rise/fall target delay encoded settings to the accessible read DQS DQ rise/fall encoded target delay observation registers for slice 0.
0x4078 CTLPHY_WRAP__CTL_CFG__CTLCFG_DENALI_PHY_30 access per field
  [29:24] PHY_WRLVL_CAPTURE_CNT_0 rw — Number of samples to take at each DQS target delay setting during write leveling for slice 0.
  [17:16] PHY_WRLVL_ALGO_0 rw — Write leveling algorithm selection for slice 0.
  [8] SC_PHY_LVL_DEBUG_CONT_0 wo — Allows the leveling state machine to advance [when in debug mode] for slice 0. Set to 1 to trigger. WRITE-ONLY
  [0] PHY_LVL_DEBUG_MODE_0 rw — Enables leveling debug mode for slice 0. Set to 1 to enable.
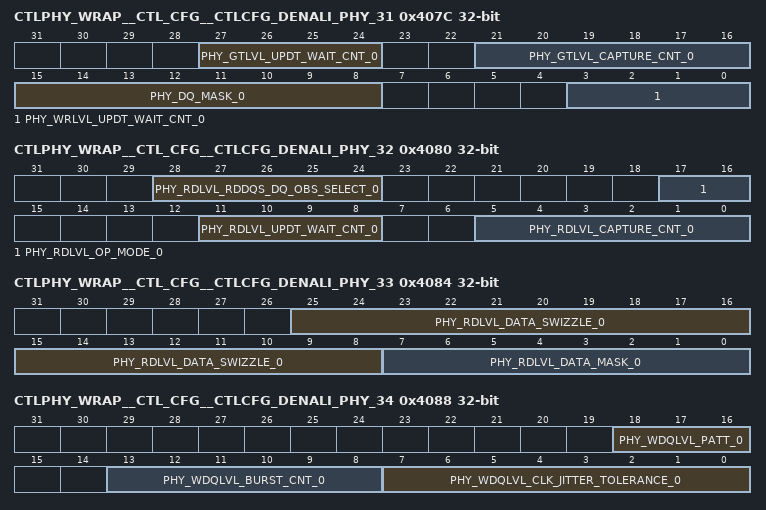
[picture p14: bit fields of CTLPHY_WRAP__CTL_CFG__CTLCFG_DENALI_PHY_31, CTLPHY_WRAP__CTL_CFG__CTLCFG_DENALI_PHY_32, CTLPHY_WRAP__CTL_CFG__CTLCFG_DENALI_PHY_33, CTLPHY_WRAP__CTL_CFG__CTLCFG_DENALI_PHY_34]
0x407C CTLPHY_WRAP__CTL_CFG__CTLCFG_DENALI_PHY_31
  [27:24] PHY_GTLVL_UPDT_WAIT_CNT_0 — Number of cycles + 4 to wait after changing DQS target delay setting during gate training for slice 0. The valid range is 0x0 to 0xB.
  [21:16] PHY_GTLVL_CAPTURE_CNT_0 — Number of samples to take at each DQS target delay setting during gate training for slice 0.
  [15:8] PHY_DQ_MASK_0 — For ECC slice, should set this register to do DQ bit mask for slice 0.
  [3:0] PHY_WRLVL_UPDT_WAIT_CNT_0 — Number of cycles to wait after changing DQS target delay setting during write leveling for slice 0.
0x4080 CTLPHY_WRAP__CTL_CFG__CTLCFG_DENALI_PHY_32
  [28:24] PHY_RDLVL_RDDQS_DQ_OBS_SELECT_0 — Select value to map an individual DQ data window leading/trailing edge to the leading/trailing edge observation registers during read leveling for slice 0.
  [17:16] PHY_RDLVL_OP_MODE_0 — Read leveling algorithm select for slice 0. Clear to 0 to move linearly from left to right. Set to 1 to start inside the window, move left and then move right.
  [11:8] PHY_RDLVL_UPDT_WAIT_CNT_0 — Number of cycles to wait after changing DQS target delay setting during read leveling for slice 0.
  [5:0] PHY_RDLVL_CAPTURE_CNT_0 — Number of samples to take at each DQS target delay setting during read leveling for slice 0.
0x4084 CTLPHY_WRAP__CTL_CFG__CTLCFG_DENALI_PHY_33
  [25:8] PHY_RDLVL_DATA_SWIZZLE_0 — Read level bit swizzling for DDR4 operation for slice 0.
  [7:0] PHY_RDLVL_DATA_MASK_0 — Per-bit mask for read leveling for slice 0. If all bits are not used, only 1 bit should be cleared to 0.
0x4088 CTLPHY_WRAP__CTL_CFG__CTLCFG_DENALI_PHY_34
  [18:16] PHY_WDQLVL_PATT_0 — Defines the training patterns to be used during the write data leveling sequence for slice 0. Bit [0] corresponds to the LFSR data training pattern. Bit [1] corresponds to the CLK data training pattern. Bit [2] corresponds to user-defined data pattern training. If multiple bits are set, the training for each of the chosen patterns will be executed and the settings that give the smallest data valid window eye will be chosen.
  [13:8] PHY_WDQLVL_BURST_CNT_0 — Defines the write/read burst length in bytes during the write data leveling sequence for slice 0.
  [7:0] PHY_WDQLVL_CLK_JITTER_TOLERANCE_0 — Defines the minimum gap requirment for the LE and TE window for slice 0.
0x408C CTLPHY_WRAP__CTL_CFG__CTLCFG_DENALI_PHY_35
  [27:24] PHY_WDQLVL_DQDM_OBS_SELECT_0 — Select value to map an individual DQ data window leading/trailing edge to the leading/trailing edge observation registers during write data leveling for slice 0.
  [19:16] PHY_WDQLVL_UPDT_WAIT_CNT_0 — Number of cycles to wait after changing the DQ target delay setting during write data leveling for slice 0.
  [10:0] PHY_WDQLVL_DQDM_SLV_DLY_JUMP_OFFSET_0 — Defines the target delay jump value when the TE window is found and begin to serch TE window for slice 0.
0x4090 CTLPHY_WRAP__CTL_CFG__CTLCFG_DENALI_PHY_36 access per field
  [24] SC_PHY_WDQLVL_CLR_PREV_RESULTS_0 wo — Clears the previous result value to allow a clean slate comparison for future write DQ leveling results for slice 0. Set to 1 to trigger. WRITE-ONLY
  [19:16] PHY_WDQLVL_DM_DLY_STEP_0 rw — The target delay line step for DM training for slice 0.
  [15:8] PHY_WDQLVL_DQ_SLV_DELTA_0 rw — The margin for DQ0-7's LE and TE dealy to make sure the DQ bits can work during DM training for slice 0.
  [7:0] PHY_WDQLVL_PERIODIC_OBS_SELECT_0 rw — Select value to map specific information during or post periodic write data leveling for slice 0.
0x4094 CTLPHY_WRAP__CTL_CFG__CTLCFG_DENALI_PHY_37
  [8:0] PHY_WDQLVL_DATADM_MASK_0 — Per-bit mask for write data leveling for slice 0. Set to 1 to mask any bit from the leveling process.
{0x4000+4i} CTLPHY_WRAP__CTL_CFG__CTLCFG_DENALI_PHY_{i} (i=38..41)
  [31:0] PHY_USER_PATT{i-38}_0 — User-defined pattern to be used during write data leveling for slice 0. This register holds the bytes {4i-149} to {4i-152} written/read from device.
0x40A8 CTLPHY_WRAP__CTL_CFG__CTLCFG_DENALI_PHY_42
  [16] PHY_NTP_MULT_TRAIN_0 — Control for single pass only No-Topology training for slice 0.
  [15:0] PHY_USER_PATT4_0 — User-defined pattern to be used during write data leveling for slice 0. This register holds the DM bit for the 15 to 0 DQ written/read from device.
0x40AC CTLPHY_WRAP__CTL_CFG__CTLCFG_DENALI_PHY_43
  [25:16] PHY_NTP_PERIOD_THRESHOLD_0 — Threshold Criteria of period threshold after No-Topology training is completed for slice 0.
  [9:0] PHY_NTP_EARLY_THRESHOLD_0 — Threshold Criteria of early threshold after No-Topology training is completed for slice 0.
0x40B0 CTLPHY_WRAP__CTL_CFG__CTLCFG_DENALI_PHY_44
  [25:16] PHY_NTP_PERIOD_THRESHOLD_MAX_0 — Maximum Threshold that phy_clk_wrdqs_target_delay could cross boundary, to set period threshold/early threshold after No-Topology training is completed for slice 0.
  [9:0] PHY_NTP_PERIOD_THRESHOLD_MIN_0 — Minimum Threshold that phy_clk_wrdqs_target_delay could cross boundary, to set period threshold/early threshold after No-Topology training is completed for slice 0.
0x40B4 CTLPHY_WRAP__CTL_CFG__CTLCFG_DENALI_PHY_45 access per field
  [23:16] PHY_FIFO_PTR_OBS_0 ro — Observation register containing read entry FIFO pointers for slice 0. READ-ONLY
  [13:8] SC_PHY_MANUAL_CLEAR_0 wo — Manual reset/clear of internal logic for slice 0. Bit [0] initiates manual setup of the read DQS gate. Bit [1] is reset of read entry FIFO pointers. Bit [2] is reset of controller delay min/max lock values. Bit [3] is manual reset of controller delay unlock counter. Bit [4] is reset of leveling error bit in the leveling status registers. Bit [5] is clearing of the gate tracking observation register. Set each bit to 1 to initiate/reset. WRITE-ONLY
  [0] PHY_CALVL_VREF_DRIVING_SLICE_0 rw — Indicates if slice 0 is used to drive the VREF value to the device during CA training.
0x40B8 CTLPHY_WRAP__CTL_CFG__CTLCFG_DENALI_PHY_46 ro reset 0x100000
  [31:0] PHY_LPBK_RESULT_OBS_0 — Observation register containing loopback status/results for slice 0. READ-ONLY
0x40BC CTLPHY_WRAP__CTL_CFG__CTLCFG_DENALI_PHY_47 ro
  [26:16] PHY_MASTER_DLY_LOCK_OBS_0 — Observation register containing controller delay results for slice 0. READ-ONLY
  [15:0] PHY_LPBK_ERROR_COUNT_OBS_0 — Observation register containing total number of loopback error data for slice 0. READ-ONLY
0x40C0 CTLPHY_WRAP__CTL_CFG__CTLCFG_DENALI_PHY_48 ro
  [31:24] PHY_RDDQS_DQ_RISE_ADDER_SLV_DLY_ENC_OBS_0 — Observation register containing read DQS DQ rising edge adder target delay encoded value for slice 0. READ-ONLY
  [23:16] PHY_MEAS_DLY_STEP_VALUE_0 — Observation register containing fraction of the cycle in 1 delay element, numerator with demominator of 512, for slice 0. READ-ONLY
  [14:8] PHY_RDDQS_BASE_SLV_DLY_ENC_OBS_0 — Observation register containing read DQS base target delay encoded value for slice 0. READ-ONLY
  [6:0] PHY_RDDQ_SLV_DLY_ENC_OBS_0 — Observation register containing read DQ target delay encoded values for slice 0. READ-ONLY
0x40C4 CTLPHY_WRAP__CTL_CFG__CTLCFG_DENALI_PHY_49 ro
  [30:24] PHY_WRDQS_BASE_SLV_DLY_ENC_OBS_0 — Observation register containing write DQS base target delay encoded value for slice 0. READ-ONLY
  [18:8] PHY_RDDQS_GATE_SLV_DLY_ENC_OBS_0 — Observation register containing read DQS gate target delay encoded value for slice 0. READ-ONLY
  [7:0] PHY_RDDQS_DQ_FALL_ADDER_SLV_DLY_ENC_OBS_0 — Observation register containing read DQS DQ falling edge adder target delay encoded value for slice 0. READ-ONLY
0x40C8 CTLPHY_WRAP__CTL_CFG__CTLCFG_DENALI_PHY_50 ro
  [18:16] PHY_WR_SHIFT_OBS_0 — Observation register containing automatic half cycle and cycle shift values for slice 0. READ-ONLY
  [15:8] PHY_WR_ADDER_SLV_DLY_ENC_OBS_0 — Observation register containing write adder target delay encoded value for slice 0. READ-ONLY
  [7:0] PHY_WRDQ_BASE_SLV_DLY_ENC_OBS_0 — Observation register containing write DQ base target delay encoded value for slice 0. READ-ONLY
0x40CC CTLPHY_WRAP__CTL_CFG__CTLCFG_DENALI_PHY_51 ro
  [25:16] PHY_WRLVL_HARD1_DELAY_OBS_0 — Observation register containing write leveling first hard 1 DQS target delay for slice 0. READ-ONLY
  [9:0] PHY_WRLVL_HARD0_DELAY_OBS_0 — Observation register containing write leveling last hard 0 DQS target delay for slice 0. READ-ONLY
0x40D0 CTLPHY_WRAP__CTL_CFG__CTLCFG_DENALI_PHY_52 ro
  [20:0] PHY_WRLVL_STATUS_OBS_0 — Observation register containing write leveling status for slice 0. READ-ONLY
0x40D4 CTLPHY_WRAP__CTL_CFG__CTLCFG_DENALI_PHY_53 ro
  [25:16] PHY_GATE_SMPL2_SLV_DLY_ENC_OBS_0 — Observation register containing gate sample2 target delay encoded values for slice 0. READ-ONLY
  [9:0] PHY_GATE_SMPL1_SLV_DLY_ENC_OBS_0 — Observation register containing gate sample1 target delay encoded values for slice 0. READ-ONLY
0x40D8 CTLPHY_WRAP__CTL_CFG__CTLCFG_DENALI_PHY_54 ro
  [29:16] PHY_GTLVL_HARD0_DELAY_OBS_0 — Observation register containing gate training first hard 0 DQS target delay for slice 0. READ-ONLY
  [15:0] PHY_WRLVL_ERROR_OBS_0 — Observation register containing write leveling error status for slice 0. READ-ONLY
0x40DC CTLPHY_WRAP__CTL_CFG__CTLCFG_DENALI_PHY_55 ro
  [13:0] PHY_GTLVL_HARD1_DELAY_OBS_0 — Observation register containing gate training last hard 1 DQS target delay for slice 0. READ-ONLY
0x40E0 CTLPHY_WRAP__CTL_CFG__CTLCFG_DENALI_PHY_56 ro
  [17:0] PHY_GTLVL_STATUS_OBS_0 — Observation register containing gate training status for slice 0. READ-ONLY
0x40E4 CTLPHY_WRAP__CTL_CFG__CTLCFG_DENALI_PHY_57 ro
  [25:16] PHY_RDLVL_RDDQS_DQ_TE_DLY_OBS_0 — Observation register containing read leveling data window trailing edge target delay setting for slice 0. READ-ONLY
  [9:0] PHY_RDLVL_RDDQS_DQ_LE_DLY_OBS_0 — Observation register containing read leveling data window leading edge target delay setting for slice 0. READ-ONLY
0x40E8 CTLPHY_WRAP__CTL_CFG__CTLCFG_DENALI_PHY_58 ro
  [1:0] PHY_RDLVL_RDDQS_DQ_NUM_WINDOWS_OBS_0 — Observation register containing read leveling number of windows found for slice 0. READ-ONLY
0x40EC CTLPHY_WRAP__CTL_CFG__CTLCFG_DENALI_PHY_59 ro
  [31:0] PHY_RDLVL_STATUS_OBS_0 — Observation register containing read leveling status for slice 0. READ-ONLY
0x40F0 CTLPHY_WRAP__CTL_CFG__CTLCFG_DENALI_PHY_60 ro reset 0x7FF0000
  [26:16] PHY_WDQLVL_DQDM_TE_DLY_OBS_0 — Observation register containing write data leveling data window trailing edge target delay setting for slice 0. READ-ONLY
  [10:0] PHY_WDQLVL_DQDM_LE_DLY_OBS_0 — Observation register containing write data leveling data window leading edge target delay setting for slice 0. READ-ONLY
0x40F4 CTLPHY_WRAP__CTL_CFG__CTLCFG_DENALI_PHY_61 ro
  [31:0] PHY_WDQLVL_STATUS_OBS_0 — Observation register containing write data leveling status for slice 0. READ-ONLY
0x40F8 CTLPHY_WRAP__CTL_CFG__CTLCFG_DENALI_PHY_62 ro
  [31:0] PHY_WDQLVL_PERIODIC_OBS_0 — Observation register containing periodic write data leveling status for slice 0. READ-ONLY
0x40FC CTLPHY_WRAP__CTL_CFG__CTLCFG_DENALI_PHY_63
  [30:0] PHY_DDL_MODE_0 — DDL mode for slice 0.
0x4100 CTLPHY_WRAP__CTL_CFG__CTLCFG_DENALI_PHY_64
  [5:0] PHY_DDL_MASK_0 — DDL mask for slice 0.
0x4104 CTLPHY_WRAP__CTL_CFG__CTLCFG_DENALI_PHY_65 ro
  [31:0] PHY_DDL_TEST_OBS_0 — DDL test observation for slice 0. READ-ONLY
0x4108 CTLPHY_WRAP__CTL_CFG__CTLCFG_DENALI_PHY_66 ro
  [31:0] PHY_DDL_TEST_MSTR_DLY_OBS_0 — DDL test observation delays for slice 0 controller DDL. READ-ONLY
0x410C CTLPHY_WRAP__CTL_CFG__CTLCFG_DENALI_PHY_67
  [24:16] PHY_RX_CAL_DQ0_0 — RX Calibration codes for DQ0 for slice 0. Bits [5:0] contain rx_cal_code_down. Bits [11:6] contain rx_cal_code_up. Bits [17:12] contain rx_cal_code2_down. Bits [23:18] contain rx_cal_code2_up.
  [8] PHY_LP4_WDQS_OE_EXTEND_0 — LPDDR4 write preamble extension enable for slice 0.
  [7:0] PHY_DDL_TRACK_UPD_THRESHOLD_0 — Specify threshold value for PHY init update tracking for slice 0.
{0x4000+4i} CTLPHY_WRAP__CTL_CFG__CTLCFG_DENALI_PHY_{i} (i=68..70)
  [24:16] PHY_RX_CAL_DQ{2i-134}_0 — RX Calibration codes for DQ{2i-134} for slice 0. Bits [5:0] contain rx_cal_code_down. Bits [11:6] contain rx_cal_code_up. Bits [17:12] contain rx_cal_code2_down. Bits [23:18] contain rx_cal_code2_up.
  [8:0] PHY_RX_CAL_DQ{2i-135}_0 — RX Calibration codes for DQ{2i-135} for slice 0. Bits [5:0] contain rx_cal_code_down. Bits [11:6] contain rx_cal_code_up. Bits [17:12] contain rx_cal_code2_down. Bits [23:18] contain rx_cal_code2_up.
0x411C CTLPHY_WRAP__CTL_CFG__CTLCFG_DENALI_PHY_71
  [8:0] PHY_RX_CAL_DQ7_0 — RX Calibration codes for DQ7 for slice 0. Bits [5:0] contain rx_cal_code_down. Bits [11:6] contain rx_cal_code_up. Bits [17:12] contain rx_cal_code2_down. Bits [23:18] contain rx_cal_code2_up.
0x4120 CTLPHY_WRAP__CTL_CFG__CTLCFG_DENALI_PHY_72
  [17:0] PHY_RX_CAL_DM_0 — RX Calibration codes for DM for slice 0. Bits [5:0] contain rx_cal_code_down. Bits [11:6] contain rx_cal_code_up. Bits [17:12] contain rx_cal_code2_down. Bits [23:18] contain rx_cal_code2_up.
0x4124 CTLPHY_WRAP__CTL_CFG__CTLCFG_DENALI_PHY_73
  [24:16] PHY_RX_CAL_FDBK_0 — RX Calibration codes for FDBK for slice 0. Bits [5:0] contain rx_cal_code_down. Bits [11:6] contain rx_cal_code_up. Bits [17:12] contain rx_cal_code2_down. Bits [23:18] contain rx_cal_code2_up.
  [8:0] PHY_RX_CAL_DQS_0 — RX Calibration codes for DQS for slice 0. Bits [5:0] contain rx_cal_code_down. Bits [11:6] contain rx_cal_code_up. Bits [17:12] contain rx_cal_code2_down. Bits [23:18] contain rx_cal_code2_up.
0x4128 CTLPHY_WRAP__CTL_CFG__CTLCFG_DENALI_PHY_74
  [31:24] PHY_DATA_DC_CAL_SAMPLE_WAIT_0 — Determines number of cycles to wait for each sample for slice 0.
  [20:16] PHY_STATIC_TOG_DISABLE_0 — Control to disable toggle during static activity for slice 0. bit0: Write path delay line disable; bit1: Read path delay line disable; bit2: Read data path disable; bit3: clk_phy disable; bit4: controller delay line disable.
  [10:0] PHY_PAD_RX_BIAS_EN_0 — Controls RX_BIAS_EN pin for each pad for slice 0.
0x412C CTLPHY_WRAP__CTL_CFG__CTLCFG_DENALI_PHY_75
  [31:24] PHY_DATA_DC_ADJUST_SAMPLE_CNT_0 — Duty cycle adjust sample count for slice 0.
  [21:16] PHY_DATA_DC_ADJUST_START_0 — Duty cycle adjust starting value for slice 0.
  [9:8] PHY_DATA_DC_WEIGHT_0 — Determines weight of average calculating for slice 0.
  [7:0] PHY_DATA_DC_CAL_TIMEOUT_0 — Determines timeout number of iteration for slice 0.
0x4130 CTLPHY_WRAP__CTL_CFG__CTLCFG_DENALI_PHY_76
  [24] PHY_DATA_DC_CAL_START_0 — Manual trigger for DCC for slice 0.
  [16] PHY_DATA_DC_CAL_POLARITY_0 — Calibration polarity for slice 0.
  [8] PHY_DATA_DC_ADJUST_DIRECT_0 — Adjust direction for slice 0.
  [7:0] PHY_DATA_DC_ADJUST_THRSHLD_0 — Duty cycle adjust threshold around the mid-point for slice 0.
0x4134 CTLPHY_WRAP__CTL_CFG__CTLCFG_DENALI_PHY_77 reset 0x1
  [24] PHY_RDPATH_GATE_DISABLE_0 — Data slice read path power reduction disable for slice 0.
  [16] PHY_SLV_DLY_CTRL_GATE_DISABLE_0 — Data slice slv_dly_control block power reduction disable for slice 0.
  [10:8] PHY_FDBK_PWR_CTRL_0 — Shutoff gate feedback IO to reduce power for slice 0.
  [1:0] PHY_DATA_DC_SW_RANK_0 — Rank selection for software based duty cycle correction for slice 0.
0x4138 CTLPHY_WRAP__CTL_CFG__CTLCFG_DENALI_PHY_78
  [8] PHY_SLICE_PWR_RDC_DISABLE_0 — Data slice power reduction disable for slice 0.
  [0] PHY_DCC_RXCAL_CTRL_GATE_DISABLE_0 — Data slice DCC and RX_CAL block power reduction disable for slice 0.
0x413C CTLPHY_WRAP__CTL_CFG__CTLCFG_DENALI_PHY_79
  [26:24] PHY_DQS_TSEL_ENABLE_0 — Operation type tsel enables for DQS signals for slice 0. Bit [0] enables tsel_en during read cycles. Bit [1] enables tsel_en during write cycles. Bit [2] enables tsel_en during idle cycles. Set each bit to 1 to enable.
  [23:8] PHY_DQ_TSEL_SELECT_0 — Operation type tsel select values for DQ/DM signals for slice 0.
  [2:0] PHY_DQ_TSEL_ENABLE_0 — Operation type tsel enables for DQ/DM signals for slice 0. Bit [0] enables tsel_en during read cycles. Bit [1] enables tsel_en during write cycles. Bit [2] enables tsel_en during idle cycles. Set each bit to 1 to enable.
0x4140 CTLPHY_WRAP__CTL_CFG__CTLCFG_DENALI_PHY_80
  [30:24] PHY_VREF_INITIAL_START_POINT_0 — Data slice initial VREF training start value for slice 0.
  [17:16] PHY_TWO_CYC_PREAMBLE_0 — 2 cycle preamble support for slice 0. Bit [0] controls the 2 cycle read preamble. Bit [1] controls the 2 cycle write preamble. Set each bit to 1 to enable.
  [15:0] PHY_DQS_TSEL_SELECT_0 — Operation type tsel select values for DQS signals for slice 0.
0x4144 CTLPHY_WRAP__CTL_CFG__CTLCFG_DENALI_PHY_81
  [31:24] PHY_NTP_WDQ_STEP_SIZE_0 — Step size of WR DQ target delay during No-Topology training for slice 0.
  [16] PHY_NTP_TRAIN_EN_0 — Enable for No-Topology training for slice 0.
  [9:8] PHY_VREF_TRAINING_CTRL_0 — Data slice vref training enable control for slice 0.
  [6:0] PHY_VREF_INITIAL_STOP_POINT_0 — Data slice initial VREF training stop value for slice 0.
